# pse84_a0 register map
Vendor: Infineon Technologies; Series: PSE84_A0; File version: 1.0
CPU: CM33 r0p1, little endian, MPU, FPU, VTOR, 3 interrupt priority bits
Registers are 32-bit, read-write, reset 0x0 unless marked. A register's access mark holds for its fields unless they carry their own. Offsets are from the block's base; [hi:lo] are bit positions; lines under a group give offsets from that group; {n}, {i} and the like mark numbered series; 'fields as' and 'values as' point back to an identical list.

## U550 — Top level section for IP generation only, contains IP memory map
Base 0x44600000
0x00 BASE_1_0 group — Page BASE
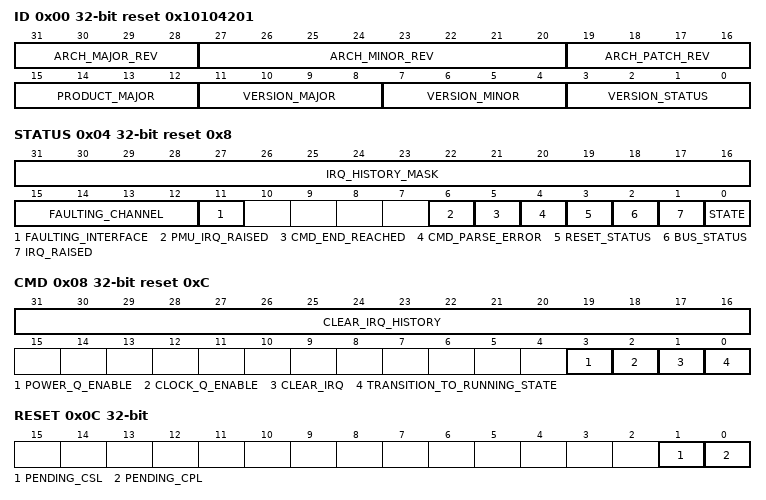
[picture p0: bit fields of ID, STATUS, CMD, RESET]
  0x00 ID ro reset 0x10104201
    [31:28] ARCH_MAJOR_REV — This is the major architecture version number, a in the architecture version a.b (Implementation-defined)
    [27:20] ARCH_MINOR_REV — This is the minor architecture version number, b in the architecture version a.b (Implementation-defined)
    [19:16] ARCH_PATCH_REV — This is the patch number of the architecture version a.b (Implementation-defined)
    [15:12] PRODUCT_MAJOR — This is the X-part of the ML00X product number (Implementation-defined)
    [11:8] VERSION_MAJOR — This is the n for the R-part of an RnPn release number
    [7:4] VERSION_MINOR — This is the n for the P-part of an RnPn release number
    [3:0] VERSION_STATUS — This is the version of the product (Implementation-defined)
  0x04 STATUS ro reset 0x8 — Register describes the current operating status of the NPU
    [31:16] IRQ_HISTORY_MASK — IRQ History mask This is used for debug purposes. Each IRQ or Event operation provides a 16-bit mask which is logically ORed into these bits. The bits can be cleared using the command register.
    [15:12] FAULTING_CHANNEL — Faulting channel on a bus abort. Read: 0=Cmd, 1=IFM, 2=Weights, 3=Scale+Bias, 4=Mem2Mem; Write: 8=OFM, 9=Mem2Mem
    [11] FAULTING_INTERFACE — Faulting interface on bus abort. 0=AXI-M0, 1=AXI-M1
    [6] PMU_IRQ_RAISED — 0=No PMU IRQ, 1=PMU IRQ raised. Cleared by using command register bit 1
    [5] CMD_END_REACHED — 0=Not reached, 1=Reached. Cleared by writing QBASE or QSIZE when the NPU is in stopped state.
    [4] CMD_PARSE_ERROR — 0=No error, 1=Command-stream parsing error detected. Can only be cleared by a reset.
    [3] RESET_STATUS — Reset is ongoing and only this register can be read (other registers read as 0 and writes are ignored). A value of 0 means the NPU is not being reset and can be accessed as normal.
    [2] BUS_STATUS — 0=OK, 1=Bus abort detected and processing halted (the NPU has reached IDLE state and does not start to process any more commands/AXI transactions). Can only be cleared by a reset.
    [1] IRQ_RAISED — Raw IRQ status: 0 = IRQ not raised, 1 = IRQ raised. IRQ is cleared using command register bit 1.
    [0] STATE — NPU state; 0 = Stopped, 1 = Running
  0x08 CMD reset 0xC — Command register, reads as last written command
    [31:16] CLEAR_IRQ_HISTORY — Clears the IRQ history mask. When bit k is set, then the corresponding bit k of the STATUS register (IRQ history) is cleared.
    [3] POWER_Q_ENABLE — Write 1 to this bit to enable power off using the Power Q-interface.
    [2] CLOCK_Q_ENABLE — Write 1 to this bit to enable clock off using the Clock Q-interface and enable the main clock gate.
    [1] CLEAR_IRQ — Write 1 to clear the IRQ status in the STATUS register. Writing 0 has no effect.
    [0] TRANSITION_TO_RUNNING_STATE — Write 1 to transition the NPU to running state. Writing 0 has no effect.
  0x0C RESET — Request Reset and new security mode
    [1] PENDING_CSL — Current security level: 0=Secure (default), 1=Non secure
    [0] PENDING_CPL — Current privilege level: 0=User (default), 1=Privileged
  0x10 QBASE0 — Base address of Command-queue bits [31 downto 0]. The address is 4-byte-aligned
    [31:0] QBASE0 — The 4-byte-aligned lower bytes of the base address value for the command stream.
  0x14 QBASE1 — Address extension bits [47 downto 32] for queue base
    [31:0] QBASE1 — The 4-byte-aligned upper bytes of the base address value for the command stream
  0x18 QREAD ro — Read offset in the command stream in bytes. Multiples of 4 in the range 0-16 MB
    [31:0] QREAD — The read offset of the current command under execution
  0x1C QCONFIG — AXI configuration for the command stream in the range 0-3. Same encoding as for REGIONCFG
    [31:0] QCONFIG — AXI configuration for the command stream in the range 0-3
  0x20 QSIZE — Size of the command stream in bytes. Multiples of 4 in the range 0-16 MB
    [31:0] QSIZE — Size of the next command stream to be executed by the NPU
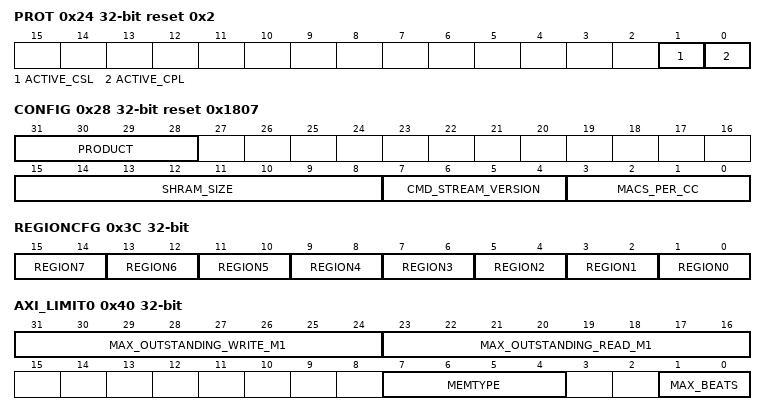
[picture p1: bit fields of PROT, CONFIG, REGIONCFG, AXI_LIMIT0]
  0x24 PROT ro reset 0x2 — Protection level configured for the NPU when acting as an AXI master
    [1] ACTIVE_CSL — Current security level. 0 = Secure 1 = Non-secure This is used as AxPROT[1] when the NPU is a master and set from Pending CSL after the reset is complete. - After a hard reset, this is set to Power-on-reset security level (PORSL), which allows for CPUs that do not support TrustZone. - After a soft reset, this is set to pending_CSL, if PPROT[1]==0, otherwise it is set to 1. For this to be effective, there must be a memory-protection controller included in the system. Depends on ROT_INIT.SECURITY_LEVEL
    [0] ACTIVE_CPL — Current privilege level. 0 = User 1 = Privilege This is used as AxPROT[0] when the NPU is a master. - After hard reset, this is set to Power-on-reset privilege level (PORPL). - After soft reset, this is set to pending_CPL, if PPROT[0]==1, otherwise it is set to 0. For this to be effective, there must be a system-level MPU built for the system. Depends on ROT_INIT.PRIVILEGE_LEVEL
  0x28 CONFIG ro reset 0x1807 — RTL configuration
    [31:28] PRODUCT — Product configuration (implementation defined)
    [15:8] SHRAM_SIZE — Size in KB of SHRAM in the range 8-48. 0x10 = 16KB 0x18 = 24KB 0x30 = 48KB
    [7:4] CMD_STREAM_VERSION — Command stream version accepted by this NPU
    [3:0] MACS_PER_CC — The log2(macs/clock cycle). Valid encoding range is 5-8 for 32-256 MACs/clock cycle. 5 = 2^5 MACS/cycle 6 = 2^6 MACS/cycle 7 = 2^7 MACS/cycle 8 = 2^8 MACS/cycle
  0x2C LOCK — Lock register. This register is designed for driver use and does not affect NPU functionality
    [31:0] LOCK — This register is designed for driver use and does not affect NPU functionality.
  0x3C REGIONCFG — Base pointer configuration. Bits[2*k+1 downto 2*k] give the memory type for REGION[k]
    [15:14] REGION7 — 0 = AXI0 port, outstanding counter 0; AXI limits are set by the AXI_LIMIT0 register. 1 = AXI0 port, outstanding counter 1; AXI limits are set by the AXI_LIMIT1 register. 2 = AXI1 port, outstanding counter 2; AXI limits are set by the AXI_LIMIT2 register. 3 = AXI1 port, outstanding counter 3; AXI limits are set by the AXI_LIMIT3 register.
    [2n+1:2n] REGION{n} (n=0..6) — same description as REGION7 field.
  0x40 AXI_LIMIT0 — AXI limits for port 0 counter 0
    [31:24] MAX_OUTSTANDING_WRITE_M1 — Maximum number of outstanding AXI write transactions, in range 0-15
    [23:16] MAX_OUTSTANDING_READ_M1 — Maximum number of outstanding AXI read transactions, in range 0-15
    [7:4] MEMTYPE
    [1:0] MAX_BEATS
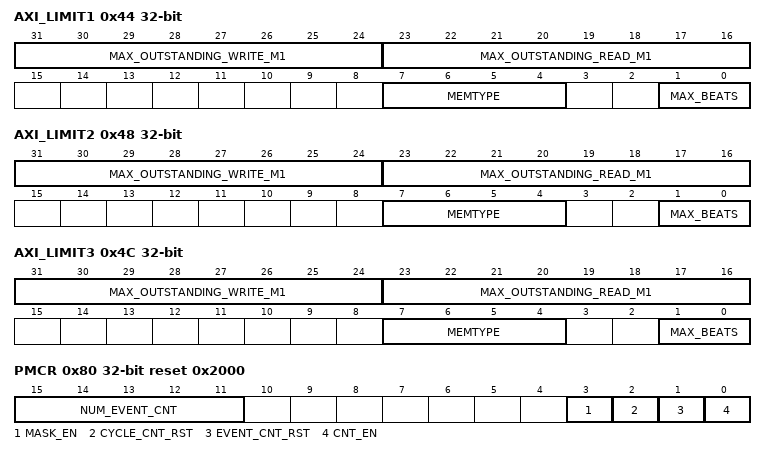
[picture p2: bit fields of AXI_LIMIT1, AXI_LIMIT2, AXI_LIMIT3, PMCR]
  0x44 AXI_LIMIT1 — AXI limits for port 0 counter 1
    fields as BASE_1_0.AXI_LIMIT0
  0x48 AXI_LIMIT2 — AXI limits for port 1 counter 2
    fields as BASE_1_0.AXI_LIMIT0
  0x4C AXI_LIMIT3 — AXI limits for port 1 counter 3
    fields as BASE_1_0.AXI_LIMIT0
0x80 BASE_POINTERS_1_0 group — Page BASE_POINTERS
  0x00 BASEP0 — Lower 32 bits of the base pointer for region index 0
    [31:0] ADDR_WORD — The low word of the 64-bit address
  0x04 BASEP1 — Upper 32-bits of the base pointer for region index 0
    [31:0] ADDR_WORD — The high word of the 64-bit address
  0x08 BASEP2 — Lower 32 bits of the base pointer for region index 1
    [31:0] ADDR_WORD — The low word of the 64-bit address
  0x0C BASEP3 — Upper 32-bits of the base pointer for region index 1
    [31:0] ADDR_WORD — The high word of the 64-bit address
  0x10 BASEP4 — Lower 32 bits of the base pointer for region index 2
    [31:0] ADDR_WORD — The low word of the 64-bit address
  0x14 BASEP5 — Upper 32-bits of the base pointer for region index 2
    [31:0] ADDR_WORD — The high word of the 64-bit address
  0x18 BASEP6 — Lower 32 bits of the base pointer for region index 3
    [31:0] ADDR_WORD — The low word of the 64-bit address
  0x1C BASEP7 — Upper 32-bits of the base pointer for region index 3
    [31:0] ADDR_WORD — The high word of the 64-bit address
  0x20 BASEP8 — Lower 32 bits of the base pointer for region index 4
    [31:0] ADDR_WORD — The low word of the 64-bit address
  0x24 BASEP9 — Upper 32-bits of the base pointer for region index 4
    [31:0] ADDR_WORD — The high word of the 64-bit address
  0x28 BASEP10 — Lower 32 bits of the base pointer for region index 5
    [31:0] ADDR_WORD — The low word of the 64-bit address
  0x2C BASEP11 — Upper 32-bits of the base pointer for region index 5
    [31:0] ADDR_WORD — The high word of the 64-bit address
  0x30 BASEP12 — Lower 32 bits of the base pointer for region index 6
    [31:0] ADDR_WORD — The low word of the 64-bit address
  0x34 BASEP13 — Upper 32-bits of the base pointer for region index 6
    [31:0] ADDR_WORD — The high word of the 64-bit address
  0x38 BASEP14 — Lower 32 bits of the base pointer for region index 7
    [31:0] ADDR_WORD — The low word of the 64-bit address
  0x3C BASEP15 — Upper 32-bits of the base pointer for region index 7
    [31:0] ADDR_WORD — The high word of the 64-bit address
0x100 PAGE_PMU_1_0 group — Page PMU
  0x80 PMCR reset 0x2000 — PMU master control register
    [15:11] NUM_EVENT_CNT ro — Number of event counters available for performance measurement
    [3] MASK_EN — PMU can be enabled/disabled by command stream operation NPU_OP_PMU_MASK
    [2] CYCLE_CNT_RST — Reset cycle counter. Writing a 1 to this register resets the cycle counter. If the cycle counter is active, it will continue counting after reset. This register bit always reads a 0.
    [1] EVENT_CNT_RST — Reset event counter. Writing a 1 to this field resets all event counters. If any counter is active, it will continue counting after reset. This register bit always reads a 0.
    [0] CNT_EN — Enable counter. This is the master switch. When the switch is disabled, the PMU is always off.
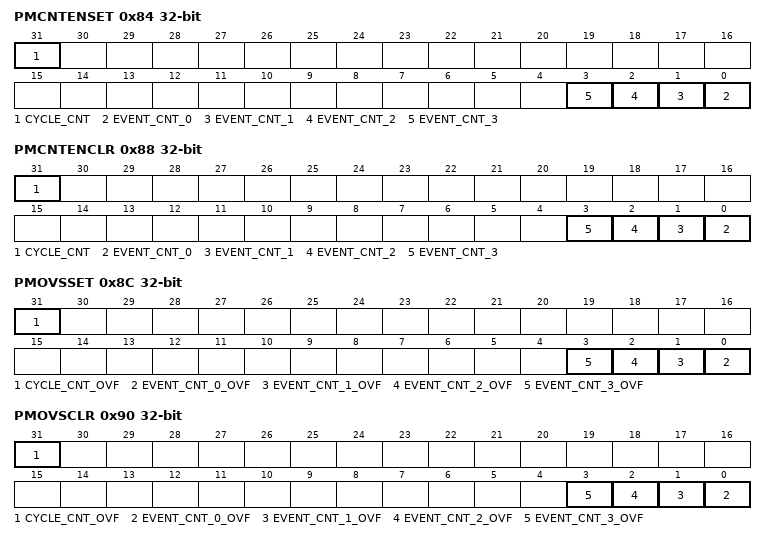
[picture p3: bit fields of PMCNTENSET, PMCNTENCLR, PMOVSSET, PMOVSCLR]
  0x84 PMCNTENSET — Count-enable set register
    [31] CYCLE_CNT — PMCCNTR enable bit. Enables the dedicated cycle counter, PMCCNTR. 0 (default) When read, it means the cycle counter is disabled. When written, it has no effect. 1 When read, it means the cycle counter is enabled. When written, it enables the cycle counter.
    [n] EVENT_CNT_{n} (n=0..3) — Event-counter enable bit for PMU_EVCNTRn, where n={n}. 0 (default) When read, it means that PMU_EVCNTRn is disabled. When written, it has no effect. 1 When read, it means that PMU_EVCNTRn event counter is enabled. When written, it enables PMU_EVCNTRn.
  0x88 PMCNTENCLR — Count-enable clear register
    [31] CYCLE_CNT — PMCCNTR disable bit. Disables the dedicated cycle counter, PMCCNTR. 0 (default) When read, it means the cycle counter is disabled. When written, it has no effect. 1 When read, it means the cycle counter is enabled. When written, it disables the cycle counter.
    [n] EVENT_CNT_{n} (n=0..3) — Event-counter disable bit for PMU_EVCNTRn, where n={n}. 0 (default) When read, it means that PMU_EVCNTRn is disabled. When written, it has no effect. 1 When read, it means that PMU_EVCNTRn event counter is enabled. When written, it disables PMU_EVCNTRn.
  0x8C PMOVSSET — Overflow-flag status set register
    [31] CYCLE_CNT_OVF — Set PMCCNTR overflow
    [n] EVENT_CNT_{n}_OVF (n=0..3) — Event-counter overflow set bit for PMU_EVCNTR{n}. 0 (default) When read, it means the cycle counter has not overflowed. When written, it has no effect. 1 When read, it means the cycle counter has overflowed. When written, it sets the overflow bit to 1.
  0x90 PMOVSCLR — Overflow-flag status clear register
    [31] CYCLE_CNT_OVF — Clear PMCCNTR overflow
    [n] EVENT_CNT_{n}_OVF (n=0..3) — Event-counter overflow clear bit for PMU_EVCNTR{n}. 0 (default) When read, it means the cycle counter has not overflowed. When written, it has no effect. 1 When read, it means the cycle counter has overflowed. When written, it clears the overflow bit to 0.
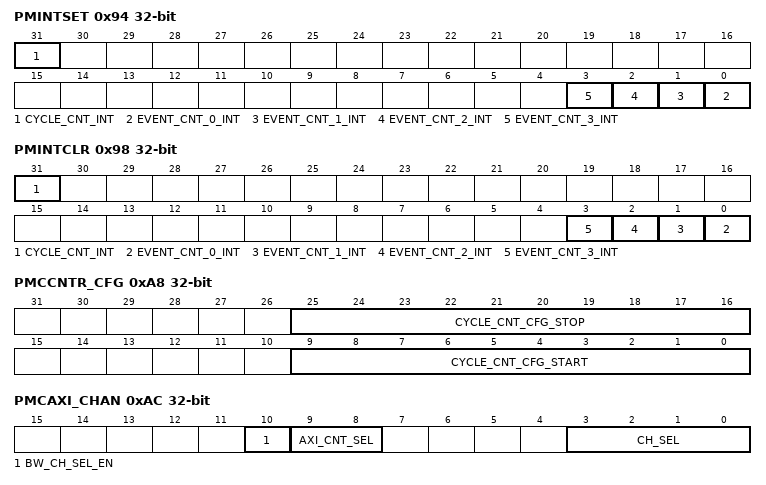
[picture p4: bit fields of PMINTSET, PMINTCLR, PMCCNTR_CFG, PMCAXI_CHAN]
  0x94 PMINTSET — Interrupt-enable set register
    [31] CYCLE_CNT_INT — PMCCNTR overflow interrupt-request enable bit 0 (default) When read, it means the cycle-counter overflow interrupt request is disabled. When written, it has no effect. 1 When read, it means the cycle-counter overflow interrupt request is enabled. When written, it enables the cycle count overflow interrupt request.
    [n] EVENT_CNT_{n}_INT (n=0..3) — Event-counter overflow interrupt-request enable bit for PMU_EVCNTR{n} 0 (default) When read, it means that the event-counter interrupt request is disabled. When written, it has no effect. 1 When read, it means that the event-counter interrupt request is enabled. When written, it enables theinterrupt request.
  0x98 PMINTCLR — Interrupt-enable clear register
    [31] CYCLE_CNT_INT — PMCCNTR overflow interrupt-request disable bit 0 (default) When read, it means the cycle-counter overflow interrupt request is disabled. When written, it has no effect. 1 When read, it means the cycle-counter overflow interrupt request is enabled. When written, it disables the cycle count overflow interrupt request.
    [n] EVENT_CNT_{n}_INT (n=0..3) — Event-counter overflow interrupt-request disable bit for PMU_EVCNTR{n} 0 (default) When read, it means that the event-counter interrupt request is disabled. When written, it has no effect. 1 When read, it means that the event-counter interrupt request is enabled. When written, it disables the interrupt request.
  0xA0 PMCCNTR_LO — Performance-monitor cycle count low register
    [31:0] CYCLE_CNT_LO — Performance-monitor cycle count low register. This represents the lower 32 bits of the dedicated 48-bit cycle counter, PMCCNTR.
  0xA4 PMCCNTR_HI — Performance-monitor cycle count high register
    [15:0] CYCLE_CNT_HI — Performance-monitor cycle count high register. This represents the higher 16 bits of the dedicated 48-bit cycle counter, PMCCNTR.
  0xA8 PMCCNTR_CFG — Set start/stop event on the cycle counter.
    [25:16] CYCLE_CNT_CFG_STOP — Cycle counter stop event
    [9:0] CYCLE_CNT_CFG_START — Cycle counter start event
  0xAC PMCAXI_CHAN — Set which AXI channel monitor
    [10] BW_CH_SEL_EN — Enable bandwidth channel selector: 0=AXI bw events measured for all channels, 1=AXI bw events measured for channel specified by CH_SEL
    [9:8] AXI_CNT_SEL — Select AXI counter to monitor for latency measurements (0=AXI0 counter0, 1=AXI0 counter1, 2=AXI1 counter 2, 3=AXI1 counter3)
    [3:0] CH_SEL — Specify the type of traffic for bandwidth or latency measurements (Read: 0=command traffic, 1=IFM traffic, 2=Weight traffic, 3=Scale+Bias, 4=Mem2Mem traffic - read direction; Write: 8=OFM traffic, 9=Mem2Mem traffic - write direction)
  {0x200+4j} PMU_EVCNTR[{j}] (j=0..3) wo — Performance monitor event counters
    [31:0] PMU_EVCNTR — Performance-monitor event counters. PMU_EVCNTR[k]: these are the four 32-bit performance counters (k=0-3).
  {0x280+4j} PMU_ENTYPER[{j}] (j=0..3) — Performance monitor event type control counters
    [9:0] EV_TYPE — Event type: 0x00 (default) no_event No event counted (the event never occurs) 0x11-0x5b - - 0x80 axi0_rd_trans_accepted AXI-0 read transfer accepted, arready & arvalid (number of read transfers) 0x81 - - 0x82 axi0_rd_data_beat_received AXI-0, rready & rvalid (read bandwidth) 0x83 axi0_rd_tran_req_stalled AXI-0, arvalid & ~arready (read stalls due memory system) 0x84 axi0_wr_trans_accepted AXI0, awready & awvalid (number write transfers) 0x85-0x86 - - 0x87 axi0_wr_data_beat_written AXI-0, wvalid wready (write bandwidth) 0x88 axi0_wr_tran_req_stalled AXI-0, awvalid & ~awready (write transfer stalls due to memory system) 0x89 axi0_wr_data_beat_stalled AXI-0, wvalid & ~wready (write beat stalls due to memory system) 0x8a-0x8b - - 0x8c axi0_enabled_cycles AXI-0, aclken_input (memory system frequency) 0x8d - - 0x8e axi0_rd_stall_limit AXI-0, check if read stalled due to AXI counter limit reached 0x8f axi0_wr_stall_limit AXI-0, check if write stalled due to AXI counter limit reached 0x180 axi1_rd_trans_accepted AXI-1 read transfer accepted, arready & arvalid (number of read transfers) 0x181 - - 0x182 axi1_rd_data_beat_received AXI-1, rready & rvalid (read bandwidth) 0x183 axi1_rd_tran_req_stalled AXI-1, arvalid & ~arready (read stalls due memory system) 0x184 axi1_wr_trans_accepted AXI-1, awready & awvalid (number write transfers) 0x185-0x186 - - 0x187 axi1_wr_data_beat_written AXI-1, wvalid & wready (write bandwidth) 0x188 axi1_wr_tran_req_stalled AXI-1, awvalid & ~awready (write transfer stalls due to memory system) 0x189 axi1_wr_data_beat_stalled AXI-1, wvalid & ~wready (write beat stalls due to memory system) 0x18a-0x18b - - 0x18c axi1_enabled_cycles AXI-1, aclken_input (memory system frequency) 0x18d - - 0x18e axi1_rd_stall_limit AXI-1, check if read stalled due to AXI counter limit reached 0x18f axi1_wr_stall_limit AXI-1, check if write stalled due to AXI counter limit reached 0xa0 axi_latency_any Any latency; measures the total number of transactions for the specified ID and interface 0xa1 axi_latency_32 Latency was >= 32 cycles 0xa2 axi_latency_64 Latency was >= 64 cycles 0xa3 axi_latency_128 Latency was >= 128 cycles 0xa4 axi_latency_256 Latency was >= 256 cycles 0xa5 axi_latency_512 Latency was >= 512 cycles 0xa6 axi_latency_1024 Latency was >= 1024 cycles
0xF00 PAGE_ID_1_0 group — Page ID and Component ID
  0xD0 PID4 ro reset 0x4 — Peripheral ID byte 4 (Arm = code 4)
    [31:0] PID4 — Byte 4 of the Peripheral ID (Lower 8 bits valid)
  {0xC0+4j} PID{j} ro (j=5..7)
    [31:0] PID{j} — Byte {j} of the Peripheral ID (Lower 8 bits valid)
  0xE0 PID0 ro reset 0x80 — Peripheral ID byte 0. This is bits[7 downto 0] of the part number.
    [31:0] PID0 — Byte 0 of the Peripheral ID (Lower 8 bits valid)
  0xE4 PID1 ro reset 0xB5 — Peripheral ID byte 1. This is bits[11 downto 8] of the part number in bits[3 downto 0], and bits[3 downto 0] of the Arm ID in bits[7 downto 4].
    [31:0] PID1 — Byte 1 of the Peripheral ID (Lower 8 bits valid)
  0xE8 PID2 ro reset 0xB — Peripheral ID byte 2. This is bits[6 downto 4] of the Arm ID in bits[2 downto 0], and bit 3 indicates format B.
    [31:0] PID2 — Byte 2 of the Peripheral ID (Lower 8 bits valid)
  0xEC PID3 ro — Peripheral ID byte 3
    [31:0] PID3 — Byte 3 of the Peripheral ID (Lower 8 bits valid)
  0xF0 CID0 ro reset 0xD — Component ID byte 0
    [31:0] CID0 — Byte 0 of the Component ID (Lower 8 bits valid)
  0xF4 CID1 ro reset 0xF0 — Component ID byte 1
    [31:0] CID1 — Byte 1 of the Component ID (Lower 8 bits valid)
  0xF8 CID2 ro reset 0x5 — Component ID byte 2
    [31:0] CID2 — Byte 2 of the Component ID (Lower 8 bits valid)
  0xFC CID3 ro reset 0xB1 — Component ID byte 3
    [31:0] CID3 — Byte 3 of the Component ID (Lower 8 bits valid)
0x1000 MXU55_CTL_1_0 group — System configuration settings
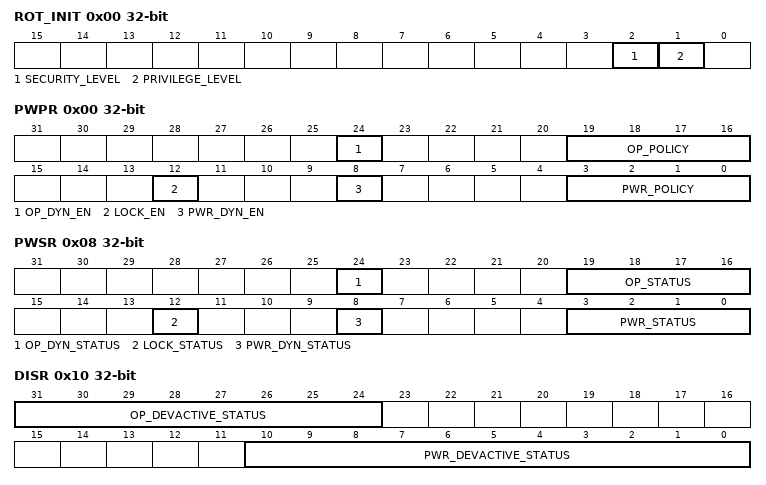
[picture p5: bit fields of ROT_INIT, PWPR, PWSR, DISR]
  0x00 ROT_INIT — Initial settings
    [2] SECURITY_LEVEL — Initial security level after power-up. 0 = Secure 1 = Non-secure
    [1] PRIVILEGE_LEVEL — Initial privilege level after power-up. 0 = User 1 = Privileged
  0x04 ACG_CTL — ACG Configuration of ARMU55 Bridge
    [0] CFG_GATE_RESP — Response type when the ACG is blocking the incoming transfers: 0: Waited transfer 1: Error response
0x2000 MXU55_PPU group — Power Policy Unit Registers for System RAM
  0x00 PWPR — Power Policy Register
    [24] OP_DYN_EN
    [19:16] OP_POLICY
    [12] LOCK_EN
    [8] PWR_DYN_EN — Power mode dynamic transition enable. When this bit is set to 1 dynamic transitions are enabled for power modes, allowing transitions to be initiated by changes on power mode DEVACTIVE inputs.
    [3:0] PWR_POLICY — Power mode policy. When static power mode transitions are enabled, PWR_DYN_EN is set to 0, this is the target power mode for the PPU. When dynamic power mode transitions are enabled, PWR_DYN_EN is set to 1, this is the minimum power mode for the PPU. This PPU supports the following modes: OFF(0), ON(8). Do not use WARM_RST(9) or other unsupported modes.
  0x04 PMER — Power Mode Emulation Register
    [0] EMU_EN
  0x08 PWSR ro — Power Status Register
    [24] OP_DYN_STATUS
    [19:16] OP_STATUS
    [12] LOCK_STATUS
    [8] PWR_DYN_STATUS — Power mode dynamic transition status. When set to 1 power mode dynamic transitions are enabled. There might be a delay in dynamic transitions becoming active or inactive if the PPU is transitioning when PWR_DYN_EN is programmed.
    [3:0] PWR_STATUS — Power mode status. These bits reflect the current power mode of the PPU. See PPU_PWPR.PWR_POLICY for power mode enumeration.
  0x10 DISR ro — Device Interface Input Current Status Register
    [31:24] OP_DEVACTIVE_STATUS
    [10:0] PWR_DEVACTIVE_STATUS — Status of the power mode DEVACTIVE inputs. There is one bit for each device interface Q-Channel DEVQACTIVE. For example, bit 0 is for Q-channel device 0 DEVQACTIVE. Refer to PPU_IDR0.DEVCHAN for device channel enumeration.
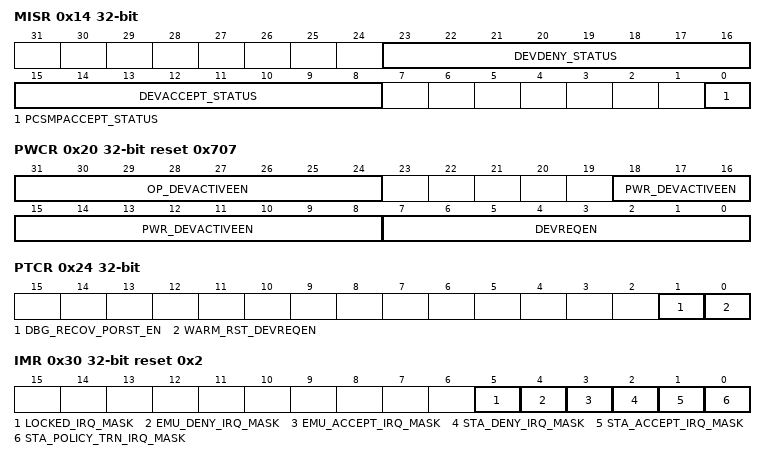
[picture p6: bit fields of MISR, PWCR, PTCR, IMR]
  0x14 MISR ro — Miscellaneous Input Current Status Register
    [23:16] DEVDENY_STATUS — Status of the device interface DEVDENY inputs. There is one bit for each device interface DEVQDENY. For example, bit 16 is for Q-Channel 0 DEVQDENY, and bit 17 for Q-Channel 1 DEVQDENY. Refer to PPU_IDR0.DEVCHAN for device channel enumeration.
    [15:8] DEVACCEPT_STATUS — Status of the device interface DEVACCEPT inputs. There is one bit for each device interface DEVQACCEPTn. For example, bit 8 is for Q-Channel 0 DEVQACCEPTn and bit 9 for Q-Channel 1 DEVQACCEPTn. Refer to PPU_IDR0.DEVCHAN for device channel enumeration.
    [0] PCSMPACCEPT_STATUS — The status of the PCSMPACCEPT input.
  0x18 STSR ro — Stored Status Register
    [7:0] STORED_DEVDENY
  0x1C UNLK — Unlock register
    [0] UNLOCK
  0x20 PWCR reset 0x707 — Power Configuration Register
    [31:24] OP_DEVACTIVEEN
    [18:8] PWR_DEVACTIVEEN — These bits enable the power mode DEVACTIVE inputs. When a bit is to 1 the related DEVACTIVE input is enabled, when set to 0 it is disabled. All available bits are reset to 1. There is one bit for each device interface Q-Channel DEVQACTIVE. For example, bit 8 is for the Q-Channel 0 DEVQACTIVE, and bit 9 for the Q-Channel 1 DEVQACTIVE. Refer to PPU_IDR0.DEVCHAN for device channel enumeration.
    [7:0] DEVREQEN — When set to 1 enables the device interface handshake for transitions. All available bits are reset to 1. There is one bit for each device interface channel. For example, bit 0 is for Q-Channel 0, and bit 1 is for Q-Channel 1. Refer to PPU_IDR0.DEVCHAN for device channel enumeration.
  0x24 PTCR — Power Mode Transition Configuration Register
    [1] DBG_RECOV_PORST_EN
    [0] WARM_RST_DEVREQEN — Transition behavior between ON and WARM_RST. This bit should not be modified when the PPU is in WARM_RST, or if the PPU is performing a transition, otherwise PPU behavior is UNPREDICTABLE. 0: The PPU does not perform a device interface handshake when transitioning between ON and WARM_RST. 1: The PPU performs a device interface handshake when transitioning between ON and WARM_RST. This disables all Q-Channels for this transition.
  0x30 IMR reset 0x2 — Interrupt Mask Register
    [5] LOCKED_IRQ_MASK ro
    [4] EMU_DENY_IRQ_MASK ro
    [3] EMU_ACCEPT_IRQ_MASK ro
    [2] STA_DENY_IRQ_MASK — Static transition denial event mask.
    [1] STA_ACCEPT_IRQ_MASK — Static transition acceptance event mask.
    [0] STA_POLICY_TRN_IRQ_MASK — Static full policy transition completion event mask.
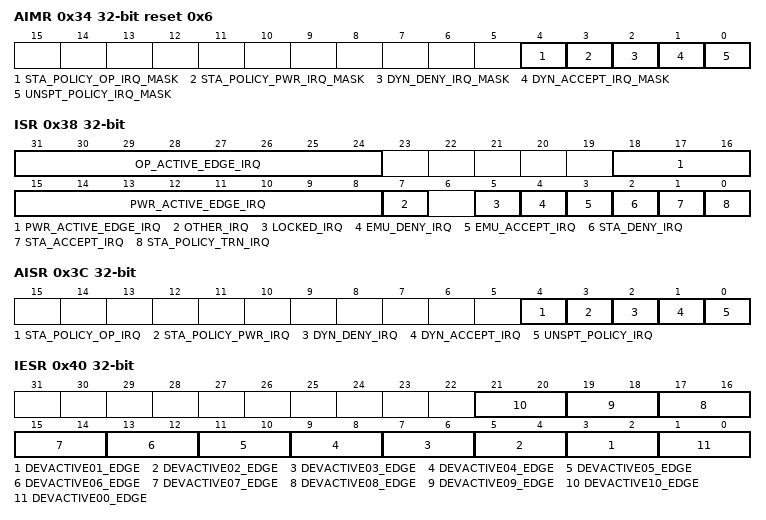
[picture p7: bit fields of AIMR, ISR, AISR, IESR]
  0x34 AIMR reset 0x6 — Additional Interrupt Mask Register
    [4] STA_POLICY_OP_IRQ_MASK ro
    [3] STA_POLICY_PWR_IRQ_MASK ro
    [2] DYN_DENY_IRQ_MASK — Dynamic transition denial event mask.
    [1] DYN_ACCEPT_IRQ_MASK — Dynamic transition acceptance event mask.
    [0] UNSPT_POLICY_IRQ_MASK — Unsupported Policy event mask.
  0x38 ISR — Interrupt Status Register
    [31:24] OP_ACTIVE_EDGE_IRQ
    [18:8] PWR_ACTIVE_EDGE_IRQ
    [7] OTHER_IRQ ro — Indicates there is an interrupt event pending in the Additional Interrupt Status Register (PPU_AISR).
    [5] LOCKED_IRQ
    [4] EMU_DENY_IRQ
    [3] EMU_ACCEPT_IRQ
    [2] STA_DENY_IRQ — Static transition denial event status.
    [1] STA_ACCEPT_IRQ — Static transition acceptance event status.
    [0] STA_POLICY_TRN_IRQ — Static full policy transition completion event status.
  0x3C AISR — Additional Interrupt Status Register
    [4] STA_POLICY_OP_IRQ
    [3] STA_POLICY_PWR_IRQ
    [2] DYN_DENY_IRQ — Dynamic transition denial event status.
    [1] DYN_ACCEPT_IRQ — Dynamic transition acceptance event status.
    [0] UNSPT_POLICY_IRQ — Unsupported Policy event status.
  0x40 IESR — Input Edge Sensitivity Register
    [2n+1:2n] DEVACTIVE{n:02}_EDGE (n=1..10)
    [1:0] DEVACTIVE00_EDGE — DEVACTIVE 0 edge sensitivity.
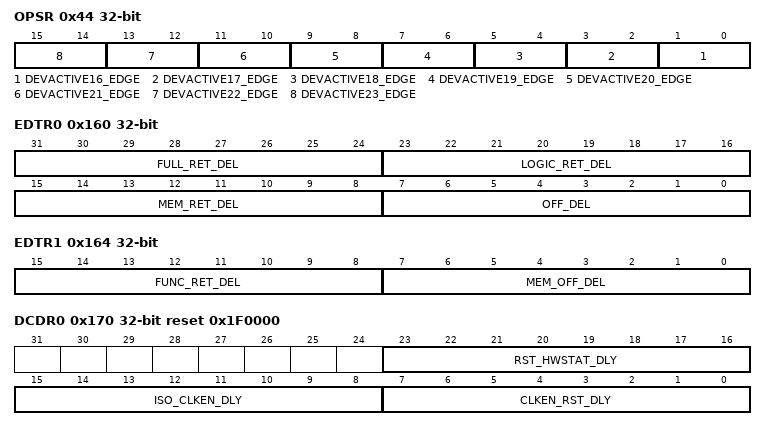
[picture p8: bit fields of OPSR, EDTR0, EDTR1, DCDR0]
  0x44 OPSR — Operating Mode Active Edge Sensitivity Register
    [2n-31:2n-32] DEVACTIVE{n}_EDGE (n=16..23)
  0x50 FUNRR — Functional Retention RAM Configuration Register
    [7:0] FUNC_RET_RAM_CFG
  0x54 FULRR — Full Retention RAM Configuration Register
    [7:0] FULL_RET_RAM_CFG
  0x58 MEMRR — Memory Retention RAM Configuration Register
    [7:0] MEM_RET_RAM_CFG
  0x160 EDTR0 — Power Mode Entry Delay Register 0
    [31:24] FULL_RET_DEL, [23:16] LOGIC_RET_DEL, [15:8] MEM_RET_DEL, [7:0] OFF_DEL
  0x164 EDTR1 — Power Mode Entry Delay Register 1
    [15:8] FUNC_RET_DEL, [7:0] MEM_OFF_DEL
  0x170 DCDR0 ro reset 0x1F0000 — Device Control Delay Configuration Register 0
    [23:16] RST_HWSTAT_DLY — Delay from clock enable assertion to reset de-assertion.
    [15:8] ISO_CLKEN_DLY
    [7:0] CLKEN_RST_DLY
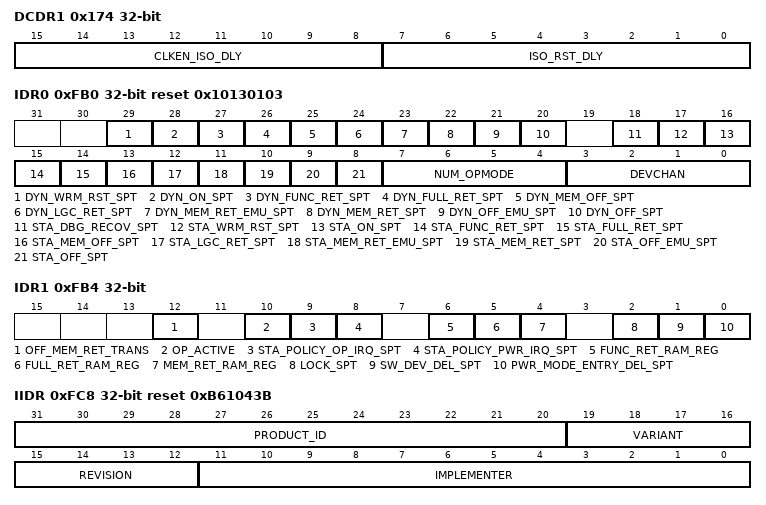
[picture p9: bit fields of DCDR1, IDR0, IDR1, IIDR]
  0x174 DCDR1 ro — Device Control Delay Configuration Register 1
    [15:8] CLKEN_ISO_DLY, [7:0] ISO_RST_DLY
  0xFB0 IDR0 ro reset 0x10130103 — PPU Identification Register 0
    [29] DYN_WRM_RST_SPT — Dynamic WARM_RST support.
    [28] DYN_ON_SPT — Dynamic ON support.
    [27] DYN_FUNC_RET_SPT — Dynamic FUNC_RET support.
    [26] DYN_FULL_RET_SPT — Dynamic FULL_RET support.
    [25] DYN_MEM_OFF_SPT — Dynamic MEM_OFF support.
    [24] DYN_LGC_RET_SPT — Dynamic LOGIC_RET support.
    [23] DYN_MEM_RET_EMU_SPT — Dynamic MEM_RET_EMU support
    [22] DYN_MEM_RET_SPT — Dynamic MEM_RET support.
    [21] DYN_OFF_EMU_SPT — Dynamic OFF_EMU support.
    [20] DYN_OFF_SPT — Dynamic OFF support.
    [18] STA_DBG_RECOV_SPT — DBG_RECOV support.
    [17] STA_WRM_RST_SPT — WARM_RST support. Ignore this bit. Do not use WARM_RST.
    [16] STA_ON_SPT — ON support.
    [15] STA_FUNC_RET_SPT — FUNC_RET support.
    [14] STA_FULL_RET_SPT — FULL_RET support.
    [13] STA_MEM_OFF_SPT — MEM_OFF support.
    [12] STA_LGC_RET_SPT — LOGIC_RET support.
    [11] STA_MEM_RET_EMU_SPT — MEM_RET_EMU support.
    [10] STA_MEM_RET_SPT — MEM_RET support.
    [9] STA_OFF_EMU_SPT — OFF_EMU support.
    [8] STA_OFF_SPT — OFF support.
    [7:4] NUM_OPMODE — No. of operating modes supported is NUM_OPMODE + 1.
    [3:0] DEVCHAN — No. of Device Interface Channels. The device enumeration is: Device 0: PDCM Device 1: U55 Device 2: U55 Sync-Down Bridge
  0xFB4 IDR1 ro — PPU Identification Register 1
    [12] OFF_MEM_RET_TRANS — OFF to MEM_RET direct transition. Indicates if direct transitions from OFF to MEM_RET and from OFF_EMU to MEM_RET_EMU are supported.
    [10] OP_ACTIVE
    [9] STA_POLICY_OP_IRQ_SPT — Operating policy transition completion event status.
    [8] STA_POLICY_PWR_IRQ_SPT — Power policy transition completion event status.
    [6] FUNC_RET_RAM_REG
    [5] FULL_RET_RAM_REG
    [4] MEM_RET_RAM_REG
    [2] LOCK_SPT — Lock and the lock interrupt event are supported.
    [1] SW_DEV_DEL_SPT — Software device delay control configuration support.
    [0] PWR_MODE_ENTRY_DEL_SPT — Power mode entry delay support.
  0xFC8 IIDR ro reset 0xB61043B — Implementation Identification Register
    [31:20] PRODUCT_ID — PPU part identification.
    [19:16] VARIANT — Major revision of the product.
    [15:12] REVISION — Minor revision of the product.
    [11:0] IMPLEMENTER — Implementer identification. [11:8] The JEP106 continuation code of the implementer. [7] Always 0. [6:0] The JEP106 identity code of the implementer. For an Arm implementation, bits [11:0] are 0x43B.
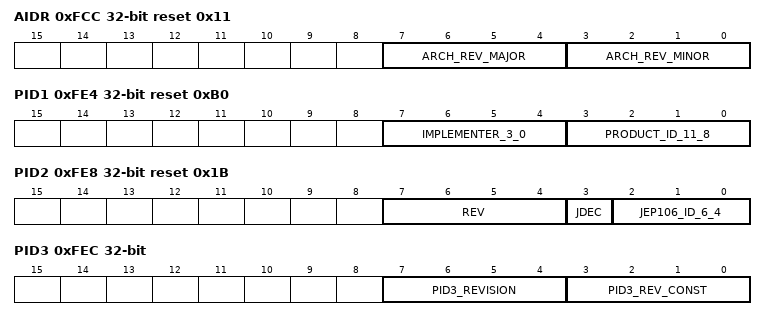
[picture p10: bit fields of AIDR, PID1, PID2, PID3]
  0xFCC AIDR ro reset 0x11 — Architecture Identification Register
    [7:4] ARCH_REV_MAJOR, [3:0] ARCH_REV_MINOR
  0xFD0 PID4 ro reset 0x4 — Implementation Defined Identification Register (PID4)
    [3:0] IMPLEMENTER_11_8 — The JEP106 continuation code of the implementer, which is 0x4 hardcoded value.
  0xFE0 PID0 ro reset 0xB6 — Implementation Defined Identification Register (PID0)
    [7:0] PRODUCT_ID_7_0 — PPU part identification bits [7:0].
  0xFE4 PID1 ro reset 0xB0 — Implementation Defined Identification Register (PID1)
    [7:4] IMPLEMENTER_3_0 — JEP106_ID bits [3:0]
    [3:0] PRODUCT_ID_11_8 — PPU part identification bits [11:8]
  0xFE8 PID2 ro reset 0x1B — Implementation Defined Identification Register (PID2)
    [7:4] REV — Revision identifier for the PCK-600 PPU: - 0x0 = r0p0. - 0x1 = r0p1, r0p2.
    [3] JDEC — Indicates the use of a JEDEC-assigned ID value.
    [2:0] JEP106_ID_6_4 — JEDEC JEP106 ID code. See also PID1.JEP_ID[3:0] and the Standard Manufacturer's Identification Code.
  0xFEC PID3 ro — Implementation Defined Identification Register (PID3)
    [7:4] PID3_REVISION — Minor revision of the product.
    [3:0] PID3_REV_CONST — Constant LOW (4 bits)
  0xFF0 ID0 ro reset 0xD — Implementation Defined Identification Register (ID0)
    [7:0] ID0 — ID0 hard coded value
  0xFF4 ID1 ro reset 0xF0 — Implementation Defined Identification Register (ID1)
    [7:0] ID1 — ID1 hardcoded value
  0xFF8 ID2 ro reset 0x5 — Implementation Defined Identification Register (ID2)
    [7:0] ID2 — ID2 hardcoded value
  0xFFC ID3 ro reset 0xB1 — Implementation Defined Identification Register (ID3)
    [7:0] ID3 — ID3 hardcoded value
0x3000 PD group — Power Domain Controller
  0x00 CTL — Power Domain Control
    [0] BLEED_EN — Activates bleed feature for the controlled power domain
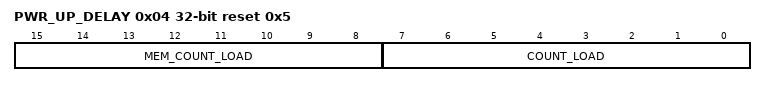
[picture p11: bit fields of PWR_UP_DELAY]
  0x04 PWR_UP_DELAY reset 0x5 — Active switch weak enable to active switch strong enable delay
    [15:8] MEM_COUNT_LOAD — Load value for counter running on clk_pwr (10MHz) providing the timing from weak MEM switch enable to strong MEM switch enable. Default is 5 for ~500ns
    [7:0] COUNT_LOAD — Load value for counter running on clk_pwr (10MHz) providing the timing from weak ACTIVE switch enable to strong ACTIVE switch enable. Default is 5 for ~500ns
